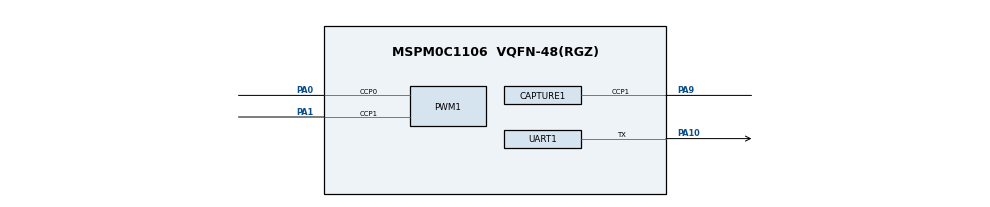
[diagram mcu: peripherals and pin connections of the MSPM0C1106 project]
//@cliArgs --device "MSPM0C1105_C1106" --package "VQFN-48(RGZ)" --part "Default"
//@v2CliArgs --device "MSPM0C1106" --package "VQFN-48(RGZ)"
 
// @cliArgs --board /ti/boards/LP_MSPM0C1106 --rtos nortos

/**
 * Import the modules used in this configuration.
 */
const Board         = scripting.addModule("/ti/driverlib/Board");
const CAPTURE       = scripting.addModule("/ti/driverlib/CAPTURE", {}, false);
const CAPTURE1      = CAPTURE.addInstance();
const CRC           = scripting.addModule("/ti/driverlib/CRC");
const PWM           = scripting.addModule("/ti/driverlib/PWM", {}, false);
const PWM1          = PWM.addInstance();
const SYSCTL        = scripting.addModule("/ti/driverlib/SYSCTL");
const TIMER         = scripting.addModule("/ti/driverlib/TIMER", {}, false);
const TIMER1        = TIMER.addInstance();
const TIMER2        = TIMER.addInstance();
const UART          = scripting.addModule("/ti/driverlib/UART", {}, false);
const UART1         = UART.addInstance();
const ProjectConfig = scripting.addModule("/ti/project_config/ProjectConfig");


CAPTURE1.timerPeriod                        = "2 ms";
CAPTURE1.captureInputMode                   = "multi";
CAPTURE1.ccIndexMulti                       = [0,1];
CAPTURE1.multi_countMode                    = "DL_TIMER_COUNT_MODE_UP";
CAPTURE1.multi_countRep                     = "DL_TIMER_REPEAT_MODE_ENABLED";
CAPTURE1.multi_cvae                         = "DL_TIMER_COUNT_AFTER_EN_ZERO";
CAPTURE1.multi_ch_zero                      = 1;
CAPTURE1.multi_ch0_input_mode               = "DL_TIMER_CC_IN_SEL_CCPX_PAIR";
CAPTURE1.multi_ch0_captEdgeDetection        = "DL_TIMER_CC_CCOND_TRIG_FALL";
CAPTURE1.interrupts                         = ["CC0_UP","CC1_UP","LOAD"];
CAPTURE1.interruptPriority                  = "0";
CAPTURE1.$name                              = "TIMER_DALI_RX";
CAPTURE1.multi_ch0_filterPeriod             = "PER_8";
CAPTURE1.multi_ch1_filterPeriod             = "PER_8";
CAPTURE1.peripheral.$assign                 = "TIMA0";
CAPTURE1.peripheral.ccp1Pin.$assign         = "PA9";

PWM1.$name                      = "PWM_0";
PWM1.peripheral.$assign         = "TIMG14";
PWM1.peripheral.ccp0Pin.$assign = "PA0";
PWM1.peripheral.ccp1Pin.$assign = "PA1";
PWM1.PWM_CHANNEL_0.dutyCycle    = 10;

SYSCTL.peripheral.$assign = "SYSCTL";

TIMER1.$name              = "TIMER_0";
TIMER1.interrupts         = ["ZERO"];
TIMER1.timerClkSrc        = "LFCLK";
TIMER1.timerPeriod        = "1.40 ms";
TIMER1.timerMode          = "PERIODIC";
TIMER1.peripheral.$assign = "TIMG8";

TIMER2.$name              = "TIMER_1";
TIMER2.timerMode          = "PERIODIC";
TIMER2.timerPeriod        = "2 ms";
TIMER2.interrupts         = ["ZERO"];
TIMER2.peripheral.$assign = "TIMG1";

UART1.$name                    = "UART_0";
UART1.enableExtend             = true;
UART1.stopBits                 = "TWO";
UART1.enableFIFO               = true;
UART1.targetBaudRate           = 1200;
UART1.uartMode                 = "DALI";
UART1.enableManchester         = true;
UART1.txFifoThreshold          = "DL_UART_TX_FIFO_LEVEL_3_4_EMPTY";
UART1.enableMSBFirst           = true;
UART1.direction                = "TX";
UART1.txPinConfig.enableConfig = true;
UART1.peripheral.$assign       = "UART0";
UART1.peripheral.txPin.$assign = "PA10";

ProjectConfig.genLibIQ           = true;
ProjectConfig.migrationCondition = true;
